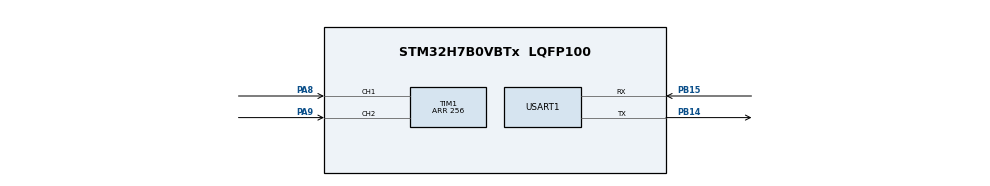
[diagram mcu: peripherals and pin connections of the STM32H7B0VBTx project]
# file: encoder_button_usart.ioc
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Mcu.Family=STM32H7
Mcu.Name=STM32H7B0VBTx
Mcu.Package=LQFP100
NVIC.PriorityGroup=NVIC_PRIORITYGROUP_4
NVIC.TIM1_BRK_IRQn=true\:0\:0\:false\:false\:true\:true\:true\:true
NVIC.TIM1_CC_IRQn=true\:0\:0\:false\:false\:true\:true\:true\:true
NVIC.TIM1_TRG_COM_IRQn=true\:0\:0\:false\:false\:true\:true\:true\:true
NVIC.TIM1_UP_IRQn=true\:0\:0\:false\:false\:true\:true\:true\:true
PA8.GPIO_PuPd=GPIO_PULLUP
PA8.Signal=S_TIM1_CH1
PA9.GPIO_PuPd=GPIO_PULLUP
PA9.Signal=S_TIM1_CH2
PB14.Mode=Asynchronous
PB14.Signal=USART1_TX
PB15.Mode=Asynchronous
PB15.Signal=USART1_RX
PH0-OSC_IN.Mode=HSE-External-Oscillator
PH0-OSC_IN.Signal=RCC_OSC_IN
PH1-OSC_OUT.Mode=HSE-External-Oscillator
PH1-OSC_OUT.Signal=RCC_OSC_OUT
ProjectManager.HeapSize=0x200
ProjectManager.StackSize=0x400
ProjectManager.TargetToolchain=STM32CubeIDE
RCC.ADCFreq_Value=48375000
RCC.APB1Freq_Value=32000000
RCC.APB2Freq_Value=32000000
RCC.APB3Freq_Value=32000000
RCC.APB4Freq_Value=32000000
RCC.CDPPRE=RCC_APB3_DIV2
RCC.CDPPRE1=RCC_APB1_DIV2
RCC.CDPPRE2=RCC_APB2_DIV2
RCC.CortexFreq_Value=64000000
RCC.DIVM1=11
RCC.HCLKFreq_Value=64000000
RCC.PLLSourceVirtual=RCC_PLLSOURCE_HSE
RCC.SRDPPRE=RCC_APB4_DIV2
RCC.SYSCLKFreq_VALUE=64000000
RCC.USBFreq_Value=140727272.72727272
SH.S_TIM1_CH1.0=TIM1_CH1,Encoder_Interface
SH.S_TIM1_CH2.0=TIM1_CH2,Encoder_Interface
TIM1.EncoderMode=TIM_ENCODERMODE_TI12
TIM1.IC1Filter=6
TIM1.IC1Polarity=TIM_ICPOLARITY_FALLING
TIM1.IC2Filter=6
TIM1.IC2Polarity=TIM_ICPOLARITY_FALLING
TIM1.Period=256
USART1.VirtualMode-Asynchronous=VM_ASYNC
board=custom

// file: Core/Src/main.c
/* USER CODE BEGIN Header */
/**
  ******************************************************************************
  * @file           : main.c
  * @brief          : Main program body
  ******************************************************************************
  * @attention
  *
  * Copyright (c) 2022 STMicroelectronics.
  * All rights reserved.
  *
  * This software is licensed under terms that can be found in the LICENSE file
  * in the root directory of this software component.
  * If no LICENSE file comes with this software, it is provided AS-IS.
  *
  ******************************************************************************
  */
/* USER CODE END Header */
#include "main.h"
#include <stdio.h>

TIM_HandleTypeDef htim1;

UART_HandleTypeDef huart1;

void SystemClock_Config(void);
static void MX_GPIO_Init(void);
static void MX_TIM1_Init(void);
static void MX_USART1_UART_Init(void);

/* USER CODE BEGIN 0 */

	uint32_t counter = 0;

	int16_t count = 0;

	int16_t position = 0;

	uint8_t str[25];

	//uint8_t pointer;

	void HAL_TIM_IC_CaptureCallback(TIM_HandleTypeDef *htim)
	{
		counter = __HAL_TIM_GET_COUNTER(htim);

		count = (int16_t)counter;

		position = count/4;

		//int16_t* pointer = &position; pointer = position;
		sprintf(str, "Testing : %lu %i %d \r\n", counter, count, position);
		HAL_UART_Transmit(&huart1,(uint8_t *)str, sizeof(str), 100);
	}

/* USER CODE END 0 */

int main(void)
{

  /* MCU Configuration--------------------------------------------------------*/

  /* Reset of all peripherals, Initializes the Flash interface and the Systick. */
  HAL_Init();

  /* Configure the system clock */
  SystemClock_Config();

  /* Initialize all configured peripherals */
  MX_GPIO_Init();
  MX_TIM1_Init();
  MX_USART1_UART_Init();
  /* USER CODE BEGIN 2 */
  HAL_TIM_Encoder_Start_IT(&htim1, TIM_CHANNEL_ALL);
  /* USER CODE END 2 */

  /* Infinite loop */
  while (1)
  {

  }
}

void SystemClock_Config(void)
{
  RCC_OscInitTypeDef RCC_OscInitStruct = {0};
  RCC_ClkInitTypeDef RCC_ClkInitStruct = {0};

  /*AXI clock gating */
  RCC->CKGAENR = 0xFFFFFFFF;

  /** Supply configuration update enable
  */
  HAL_PWREx_ConfigSupply(PWR_LDO_SUPPLY);

  /** Configure the main internal regulator output voltage
  */
  __HAL_PWR_VOLTAGESCALING_CONFIG(PWR_REGULATOR_VOLTAGE_SCALE3);

  while(!__HAL_PWR_GET_FLAG(PWR_FLAG_VOSRDY)) {}

  /** Initializes the RCC Oscillators according to the specified parameters
  * in the RCC_OscInitTypeDef structure.
  */
  RCC_OscInitStruct.OscillatorType = RCC_OSCILLATORTYPE_HSI;
  RCC_OscInitStruct.HSIState = RCC_HSI_DIV1;
  RCC_OscInitStruct.HSICalibrationValue = RCC_HSICALIBRATION_DEFAULT;
  RCC_OscInitStruct.PLL.PLLState = RCC_PLL_NONE;
  if (HAL_RCC_OscConfig(&RCC_OscInitStruct) != HAL_OK)
  {
    Error_Handler();
  }

  /** Initializes the CPU, AHB and APB buses clocks
  */
  RCC_ClkInitStruct.ClockType = RCC_CLOCKTYPE_HCLK|RCC_CLOCKTYPE_SYSCLK
                              |RCC_CLOCKTYPE_PCLK1|RCC_CLOCKTYPE_PCLK2
                              |RCC_CLOCKTYPE_D3PCLK1|RCC_CLOCKTYPE_D1PCLK1;
  RCC_ClkInitStruct.SYSCLKSource = RCC_SYSCLKSOURCE_HSI;
  RCC_ClkInitStruct.SYSCLKDivider = RCC_SYSCLK_DIV1;
  RCC_ClkInitStruct.AHBCLKDivider = RCC_HCLK_DIV1;
  RCC_ClkInitStruct.APB3CLKDivider = RCC_APB3_DIV2;
  RCC_ClkInitStruct.APB1CLKDivider = RCC_APB1_DIV2;
  RCC_ClkInitStruct.APB2CLKDivider = RCC_APB2_DIV2;
  RCC_ClkInitStruct.APB4CLKDivider = RCC_APB4_DIV2;

  if (HAL_RCC_ClockConfig(&RCC_ClkInitStruct, FLASH_LATENCY_2) != HAL_OK)
  {
    Error_Handler();
  }
}

static void MX_TIM1_Init(void)
{

  TIM_Encoder_InitTypeDef sConfig = {0};
  TIM_MasterConfigTypeDef sMasterConfig = {0};

  htim1.Instance = TIM1;
  htim1.Init.Prescaler = 0;
  htim1.Init.CounterMode = TIM_COUNTERMODE_UP;
  htim1.Init.Period = 256;
  htim1.Init.ClockDivision = TIM_CLOCKDIVISION_DIV1;
  htim1.Init.RepetitionCounter = 0;
  htim1.Init.AutoReloadPreload = TIM_AUTORELOAD_PRELOAD_DISABLE;
  sConfig.EncoderMode = TIM_ENCODERMODE_TI12;
  sConfig.IC1Polarity = TIM_ICPOLARITY_FALLING;
  sConfig.IC1Selection = TIM_ICSELECTION_DIRECTTI;
  sConfig.IC1Prescaler = TIM_ICPSC_DIV1;
  sConfig.IC1Filter = 6;
  sConfig.IC2Polarity = TIM_ICPOLARITY_FALLING;
  sConfig.IC2Selection = TIM_ICSELECTION_DIRECTTI;
  sConfig.IC2Prescaler = TIM_ICPSC_DIV1;
  sConfig.IC2Filter = 6;
  if (HAL_TIM_Encoder_Init(&htim1, &sConfig) != HAL_OK)
  {
    Error_Handler();
  }
  sMasterConfig.MasterOutputTrigger = TIM_TRGO_RESET;
  sMasterConfig.MasterOutputTrigger2 = TIM_TRGO2_RESET;
  sMasterConfig.MasterSlaveMode = TIM_MASTERSLAVEMODE_DISABLE;
  if (HAL_TIMEx_MasterConfigSynchronization(&htim1, &sMasterConfig) != HAL_OK)
  {
    Error_Handler();
  }

}

static void MX_USART1_UART_Init(void)
{

  huart1.Instance = USART1;
  huart1.Init.BaudRate = 115200;
  huart1.Init.WordLength = UART_WORDLENGTH_8B;
  huart1.Init.StopBits = UART_STOPBITS_1;
  huart1.Init.Parity = UART_PARITY_NONE;
  huart1.Init.Mode = UART_MODE_TX_RX;
  huart1.Init.HwFlowCtl = UART_HWCONTROL_NONE;
  huart1.Init.OverSampling = UART_OVERSAMPLING_16;
  huart1.Init.OneBitSampling = UART_ONE_BIT_SAMPLE_DISABLE;
  huart1.Init.ClockPrescaler = UART_PRESCALER_DIV1;
  huart1.AdvancedInit.AdvFeatureInit = UART_ADVFEATURE_NO_INIT;
  if (HAL_UART_Init(&huart1) != HAL_OK)
  {
    Error_Handler();
  }
  if (HAL_UARTEx_SetTxFifoThreshold(&huart1, UART_TXFIFO_THRESHOLD_1_8) != HAL_OK)
  {
    Error_Handler();
  }
  if (HAL_UARTEx_SetRxFifoThreshold(&huart1, UART_RXFIFO_THRESHOLD_1_8) != HAL_OK)
  {
    Error_Handler();
  }
  if (HAL_UARTEx_DisableFifoMode(&huart1) != HAL_OK)
  {
    Error_Handler();
  }

}

static void MX_GPIO_Init(void)
{

  /* GPIO Ports Clock Enable */
  __HAL_RCC_GPIOH_CLK_ENABLE();
  __HAL_RCC_GPIOB_CLK_ENABLE();
  __HAL_RCC_GPIOA_CLK_ENABLE();

}

void Error_Handler(void)
{
  __disable_irq();
  while (1)
  {
  }
}
